AUTOSAR XML (schema 4-3-0)
package /BMW/Platform/SysTime/SwcImplementations
  swc implementation ImplementationSysTime: behavior=Internal_SysTime
    code-descriptors:
      code Default: artifact-descriptors=autosar-engineering-object={short-label=Default, category=SWSRC}
package /BMW/Platform/SysTime/SwComponentTypes
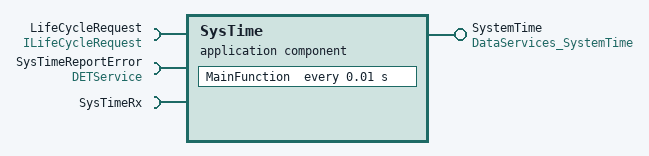
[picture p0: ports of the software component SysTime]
  application sw component type SysTime
    provide port SystemTime: server-com-spec{operation=ReadData, queue-length=1}, provided-interface=DataServices_SystemTime
    provide/require port LifeCycle: mode-switch-sender-com-spec{enhanced-mode-api=true, mode-group=Mode, queue-length=2}, mode-switch-receiver-com-spec{enhanced-mode-api=true, supports-asynchronous-mode-switch=false}, provided-required-interface=ILifeCycle
    require port LifeCycleRequest: nonqueued-receiver-com-spec{data-element=requestMode, filter=data-filter-type=ALWAYS, init-value=2}, required-interface=ILifeCycleRequest
    require port SysTimeReportError: required-interface=DETService
    require port SysTimeRx: nonqueued-receiver-com-spec{data-element=timeSignal, filter=data-filter-type=ALWAYS, init-value=0}, required-interface=SysTimeRx
    behavior Internal_SysTime: data-type-mapping=DataTMappingSet1
      exclusive area SysTimeGetTimeArea
      data received event LifeCycleRequest: start-on-event=LifeCycleHandler, data=LifeCycleRequest.requestMode
      timing event TimingEvent: disabled-mode=[LifeCycle.Mode.SYSTIME_INITIALIZED, LifeCycle.Mode.SYSTIME_STOPPED], start-on-event=MainFunction, period=0.01
      operation invoked event OpInvokedEventReadDID: start-on-event=ReadDataSystemTime, operation=SystemTime.ReadData
      data received event SysTimeRx: disabled-mode=[LifeCycle.Mode.SYSTIME_INITIALIZED, LifeCycle.Mode.SYSTIME_STOPPED], start-on-event=ReceiveSignal, data=SysTimeRx.timeSignal
      4 x runnable:
        LifeCycleHandler: mode-access-point=LifeCycle.Mode, symbol=SysTime_LifeCycleHandler
          data-read-access:
            access requestedMode: accessed-variable=LifeCycleRequest.requestMode
          mode switch point LifeCycle: mode-group=LifeCycle.Mode
          sync call sscp_DetError: operation=SysTimeReportError.ReportError, timeout=0
        MainFunction: can-enter-exclusive-area=SysTimeGetTimeArea, symbol=SysTime_MainFunction
        ReadDataSystemTime: can-enter-exclusive-area=SysTimeGetTimeArea, can-be-invoked-concurrently=true, symbol=SysTime_GetSystemTime
          sync call sscp_DetError: operation=SysTimeReportError.ReportError, timeout=0
        ReceiveSignal: can-enter-exclusive-area=SysTimeGetTimeArea, can-be-invoked-concurrently=true, symbol=SysTime_ReceiveSignal
          data-receive-point-by-arguments:
            access VariableAccess_timeSignal: accessed-variable=SysTimeRx.timeSignal
      swc service dependency SysTimeDiagnosticEventManagerService: assigned-ports=role-based-port-assignment={port-prototype=SystemTime, role=CSDataServices}
        service-needs:
          diagnostic event manager needs sn_SysTimeDiagnosticEventManagerService
      swc service dependency SysTimeDiagnosticValueServiceNeeds: assigned-ports=role-based-port-assignment={port-prototype=SystemTime, role=DataServices}
        service-needs:
          diagnostic value needs sn_DiagnosticValueServiceNeeds: did-number=5889
